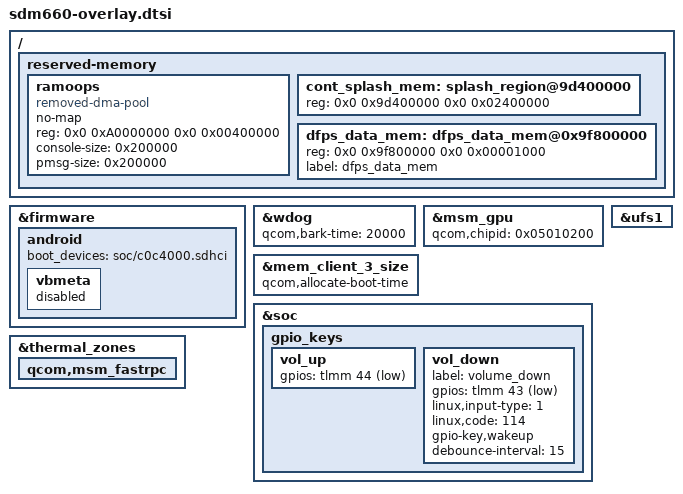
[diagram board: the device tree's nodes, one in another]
/* SPDX-License-Identifier: GPL-2.0 */

/ {
	reserved-memory {
	ramoops {
		status = "ok";
		compatible = "removed-dma-pool", "ramoops";
		no-map;
		reg = <0x0 0xA0000000 0x0 0x00400000>;
		console-size = <0x200000>;
		pmsg-size = <0x200000>;
		};

		cont_splash_mem: splash_region@9d400000 {
			reg = <0x0 0x9d400000 0x0 0x02400000>;
		};

		/delete-node/ dfps_data_mem@0x9f7ff000;

		dfps_data_mem: dfps_data_mem@0x9f800000 {
			reg = <0x0 0x9f800000 0x0 0x00001000>;
			label = "dfps_data_mem";
		};
	};
};

&firmware {
	android {
		boot_devices = "soc/c0c4000.sdhci";
		/delete-node/ fstab;

		vbmeta {
			status = "disabled";
		};
	};
};

&wdog {
	qcom,bark-time = <20000>;
};

&msm_gpu {
	/* sdm636.dtsi defaults to A509, but X00TD has A512 tweaks */
	qcom,chipid = <0x05010200>;
};

&mem_client_3_size {
		/delete-property/ qcom,allocate-on-request;

		qcom,allocate-boot-time;
};

&ufs1 {
	/delete-property/ pinctrl-names;
	/delete-property/ pinctrl-0;
	/delete-property/ pinctrl-1;
};

&soc {
	gpio_keys {
		/delete-node/ camera_focus;
		/delete-node/ camera_snapshot;

		vol_up {
			gpios = <&tlmm 44 0x1>;
		};

		vol_down {
			label = "volume_down";
			gpios = <&tlmm 43 0x1>;
			linux,input-type = <1>;
			linux,code = <114>;
			gpio-key,wakeup;
			debounce-interval = <15>;
		};
	};
};

&thermal_zones {
	/delete-node/ vbat_adc;
	/delete-node/ vbat_low;
	/delete-node/ vbat_too_low;
	qcom,msm_fastrpc {
		/delete-property/ qcom,fastrpc-adsp-sensors-pdr;
	};
};
